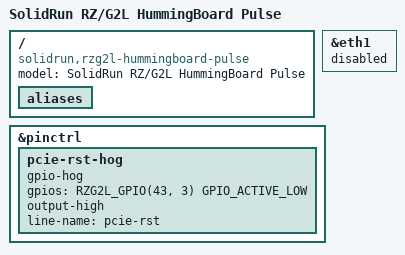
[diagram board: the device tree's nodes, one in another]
// SPDX-License-Identifier: (GPL-2.0-only OR BSD-2-Clause)
/*
 * Copyright 2025 Josua Mayer <josua@solid-run.com>
 */

/dts-v1/;

#include "r9a07g044l2.dtsi"
#include "rzg2l-sr-som.dtsi"
#include "rzg2l-hummingboard-pulse-codec.dtsi"
#include "rzg2l-hummingboard-pulse-common.dtsi"
#include "rzg2l-hummingboard-pulse-m2con.dtsi"
#include "rzg2l-hummingboard-pulse-micro-hdmi.dtsi"

/ {
	model = "SolidRun RZ/G2L HummingBoard Pulse";
	compatible = "solidrun,rzg2l-hummingboard-pulse", "solidrun,rzg2l-sr-som", "renesas,r9a07g044l2", "renesas,r9a07g044";

	aliases {
		/delete-property/ ethernet1;
	};
};

&eth1 {
	/* this board does not use second phy / ethernet on SoM */
	status = "disabled";
};

&pinctrl {
	/* RZ/G2L(C) has no PCI, keep the on-board pci nic in reset. */
	pcie-rst-hog {
		gpio-hog;
		gpios = <RZG2L_GPIO(43, 3) GPIO_ACTIVE_LOW>;
		output-high;
		line-name = "pcie-rst";
	};
};
